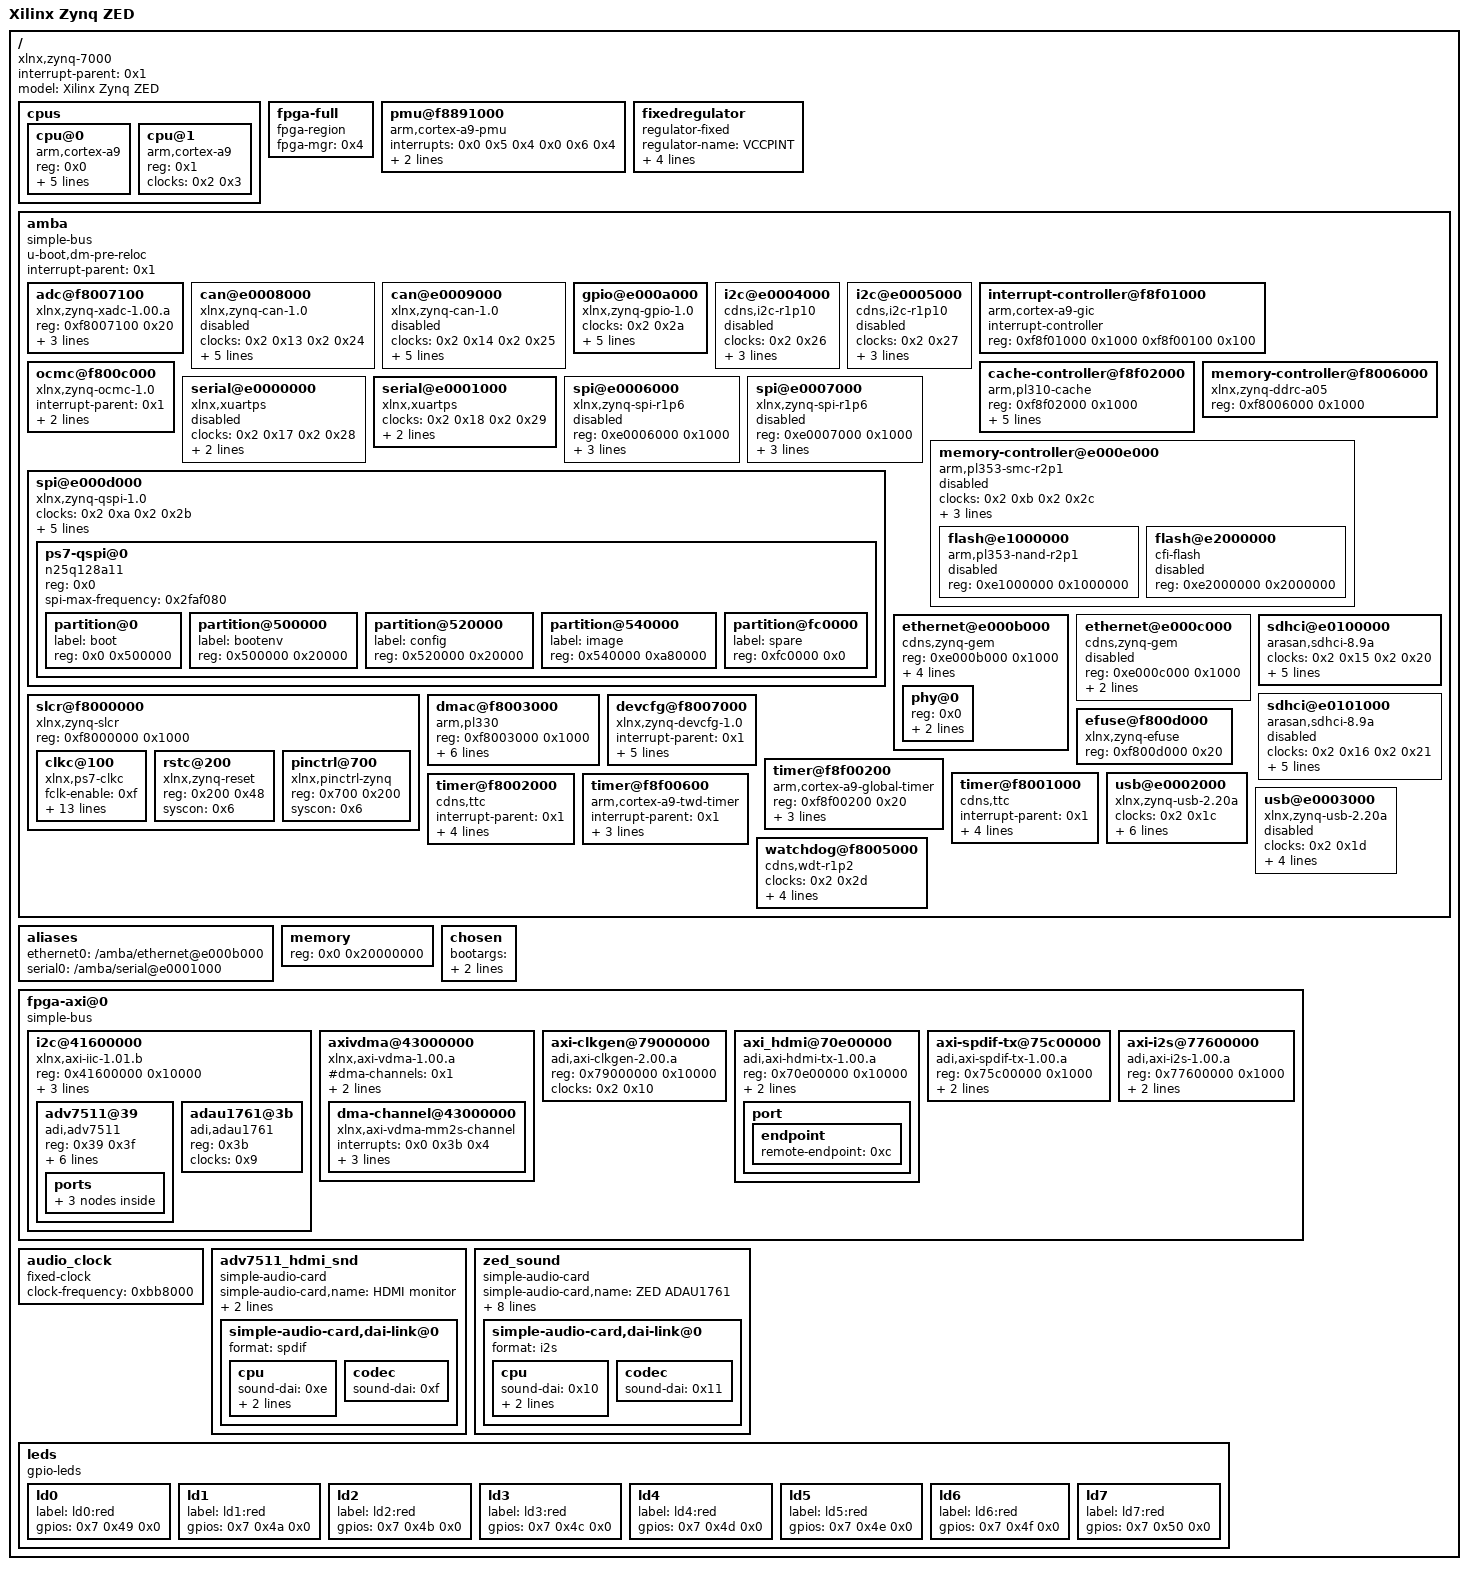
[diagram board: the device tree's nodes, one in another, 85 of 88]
/dts-v1/;

/ {
	#address-cells = <0x1>;
	#size-cells = <0x1>;
	compatible = "xlnx,zynq-7000";
	interrupt-parent = <0x1>;
	model = "Xilinx Zynq ZED";

	cpus {
		#address-cells = <0x1>;
		#size-cells = <0x0>;

		cpu@0 {
			compatible = "arm,cortex-a9";
			device_type = "cpu";
			reg = <0x0>;
			clocks = <0x2 0x3>;
			clock-latency = <0x3e8>;
			cpu0-supply = <0x3>;
			operating-points = <0xa2c2b 0xf4240 0x51616 0xf4240>;
		};

		cpu@1 {
			compatible = "arm,cortex-a9";
			device_type = "cpu";
			reg = <0x1>;
			clocks = <0x2 0x3>;
		};
	};

	fpga-full {
		compatible = "fpga-region";
		fpga-mgr = <0x4>;
		#address-cells = <0x1>;
		#size-cells = <0x1>;
		ranges;
	};

	pmu@f8891000 {
		compatible = "arm,cortex-a9-pmu";
		interrupts = <0x0 0x5 0x4 0x0 0x6 0x4>;
		interrupt-parent = <0x1>;
		reg = <0xf8891000 0x1000 0xf8893000 0x1000>;
	};

	fixedregulator {
		compatible = "regulator-fixed";
		regulator-name = "VCCPINT";
		regulator-min-microvolt = <0xf4240>;
		regulator-max-microvolt = <0xf4240>;
		regulator-boot-on;
		regulator-always-on;
		phandle = <0x3>;
	};

	amba {
		u-boot,dm-pre-reloc;
		compatible = "simple-bus";
		#address-cells = <0x1>;
		#size-cells = <0x1>;
		interrupt-parent = <0x1>;
		ranges;

		adc@f8007100 {
			compatible = "xlnx,zynq-xadc-1.00.a";
			reg = <0xf8007100 0x20>;
			interrupts = <0x0 0x7 0x4>;
			interrupt-parent = <0x1>;
			clocks = <0x2 0xc>;
		};

		can@e0008000 {
			compatible = "xlnx,zynq-can-1.0";
			status = "disabled";
			clocks = <0x2 0x13 0x2 0x24>;
			clock-names = "can_clk", "pclk";
			reg = <0xe0008000 0x1000>;
			interrupts = <0x0 0x1c 0x4>;
			interrupt-parent = <0x1>;
			tx-fifo-depth = <0x40>;
			rx-fifo-depth = <0x40>;
		};

		can@e0009000 {
			compatible = "xlnx,zynq-can-1.0";
			status = "disabled";
			clocks = <0x2 0x14 0x2 0x25>;
			clock-names = "can_clk", "pclk";
			reg = <0xe0009000 0x1000>;
			interrupts = <0x0 0x33 0x4>;
			interrupt-parent = <0x1>;
			tx-fifo-depth = <0x40>;
			rx-fifo-depth = <0x40>;
		};

		gpio@e000a000 {
			compatible = "xlnx,zynq-gpio-1.0";
			#gpio-cells = <0x2>;
			clocks = <0x2 0x2a>;
			gpio-controller;
			interrupt-controller;
			#interrupt-cells = <0x2>;
			interrupt-parent = <0x1>;
			interrupts = <0x0 0x14 0x4>;
			reg = <0xe000a000 0x1000>;
			phandle = <0x7>;
		};

		i2c@e0004000 {
			compatible = "cdns,i2c-r1p10";
			status = "disabled";
			clocks = <0x2 0x26>;
			interrupt-parent = <0x1>;
			interrupts = <0x0 0x19 0x4>;
			reg = <0xe0004000 0x1000>;
			#address-cells = <0x1>;
			#size-cells = <0x0>;
		};

		i2c@e0005000 {
			compatible = "cdns,i2c-r1p10";
			status = "disabled";
			clocks = <0x2 0x27>;
			interrupt-parent = <0x1>;
			interrupts = <0x0 0x30 0x4>;
			reg = <0xe0005000 0x1000>;
			#address-cells = <0x1>;
			#size-cells = <0x0>;
		};

		interrupt-controller@f8f01000 {
			compatible = "arm,cortex-a9-gic";
			#interrupt-cells = <0x3>;
			interrupt-controller;
			reg = <0xf8f01000 0x1000 0xf8f00100 0x100>;
			phandle = <0x1>;
		};

		cache-controller@f8f02000 {
			compatible = "arm,pl310-cache";
			reg = <0xf8f02000 0x1000>;
			interrupts = <0x0 0x2 0x4>;
			arm,data-latency = <0x3 0x2 0x2>;
			arm,tag-latency = <0x2 0x2 0x2>;
			cache-unified;
			cache-level = <0x2>;
		};

		memory-controller@f8006000 {
			compatible = "xlnx,zynq-ddrc-a05";
			reg = <0xf8006000 0x1000>;
		};

		ocmc@f800c000 {
			compatible = "xlnx,zynq-ocmc-1.0";
			interrupt-parent = <0x1>;
			interrupts = <0x0 0x3 0x4>;
			reg = <0xf800c000 0x1000>;
		};

		serial@e0000000 {
			compatible = "xlnx,xuartps", "cdns,uart-r1p8";
			status = "disabled";
			clocks = <0x2 0x17 0x2 0x28>;
			clock-names = "uart_clk", "pclk";
			reg = <0xe0000000 0x1000>;
			interrupts = <0x0 0x1b 0x4>;
		};

		serial@e0001000 {
			compatible = "xlnx,xuartps", "cdns,uart-r1p8";
			status = "okay";
			clocks = <0x2 0x18 0x2 0x29>;
			clock-names = "uart_clk", "pclk";
			reg = <0xe0001000 0x1000>;
			interrupts = <0x0 0x32 0x4>;
		};

		spi@e0006000 {
			compatible = "xlnx,zynq-spi-r1p6";
			reg = <0xe0006000 0x1000>;
			status = "disabled";
			interrupt-parent = <0x1>;
			interrupts = <0x0 0x1a 0x4>;
			clocks = <0x2 0x19 0x2 0x22>;
			clock-names = "ref_clk", "pclk";
			#address-cells = <0x1>;
			#size-cells = <0x0>;
		};

		spi@e0007000 {
			compatible = "xlnx,zynq-spi-r1p6";
			reg = <0xe0007000 0x1000>;
			status = "disabled";
			interrupt-parent = <0x1>;
			interrupts = <0x0 0x31 0x4>;
			clocks = <0x2 0x1a 0x2 0x23>;
			clock-names = "ref_clk", "pclk";
			#address-cells = <0x1>;
			#size-cells = <0x0>;
		};

		spi@e000d000 {
			clock-names = "ref_clk", "pclk";
			clocks = <0x2 0xa 0x2 0x2b>;
			compatible = "xlnx,zynq-qspi-1.0";
			status = "okay";
			interrupt-parent = <0x1>;
			interrupts = <0x0 0x13 0x4>;
			reg = <0xe000d000 0x1000>;
			#address-cells = <0x1>;
			#size-cells = <0x0>;
			is-dual = <0x0>;
			num-cs = <0x1>;

			ps7-qspi@0 {
				#address-cells = <0x1>;
				#size-cells = <0x1>;
				compatible = "n25q128a11";
				reg = <0x0>;
				spi-max-frequency = <0x2faf080>;

				partition@0 {
					label = "boot";
					reg = <0x0 0x500000>;
				};

				partition@500000 {
					label = "bootenv";
					reg = <0x500000 0x20000>;
				};

				partition@520000 {
					label = "config";
					reg = <0x520000 0x20000>;
				};

				partition@540000 {
					label = "image";
					reg = <0x540000 0xa80000>;
				};

				partition@fc0000 {
					label = "spare";
					reg = <0xfc0000 0x0>;
				};
			};
		};

		memory-controller@e000e000 {
			#address-cells = <0x1>;
			#size-cells = <0x1>;
			status = "disabled";
			clock-names = "memclk", "aclk";
			clocks = <0x2 0xb 0x2 0x2c>;
			compatible = "arm,pl353-smc-r2p1";
			interrupt-parent = <0x1>;
			interrupts = <0x0 0x12 0x4>;
			ranges;
			reg = <0xe000e000 0x1000>;

			flash@e1000000 {
				status = "disabled";
				compatible = "arm,pl353-nand-r2p1";
				reg = <0xe1000000 0x1000000>;
				#address-cells = <0x1>;
				#size-cells = <0x1>;
			};

			flash@e2000000 {
				status = "disabled";
				compatible = "cfi-flash";
				reg = <0xe2000000 0x2000000>;
				#address-cells = <0x1>;
				#size-cells = <0x1>;
			};
		};

		ethernet@e000b000 {
			compatible = "cdns,zynq-gem", "cdns,gem";
			reg = <0xe000b000 0x1000>;
			status = "okay";
			interrupts = <0x0 0x16 0x4>;
			clocks = <0x2 0x1e 0x2 0x1e 0x2 0xd>;
			clock-names = "pclk", "hclk", "tx_clk";
			#address-cells = <0x1>;
			#size-cells = <0x0>;
			phy-handle = <0x5>;
			phy-mode = "rgmii-id";

			phy@0 {
				device_type = "ethernet-phy";
				reg = <0x0>;
				marvell,reg-init = <0x3 0x10 0xff00 0x1e 0x3 0x11 0xfff0 0xa>;
				phandle = <0x5>;
			};
		};

		ethernet@e000c000 {
			compatible = "cdns,zynq-gem", "cdns,gem";
			reg = <0xe000c000 0x1000>;
			status = "disabled";
			interrupts = <0x0 0x2d 0x4>;
			clocks = <0x2 0x1f 0x2 0x1f 0x2 0xe>;
			clock-names = "pclk", "hclk", "tx_clk";
			#address-cells = <0x1>;
			#size-cells = <0x0>;
		};

		sdhci@e0100000 {
			compatible = "arasan,sdhci-8.9a";
			status = "okay";
			clock-names = "clk_xin", "clk_ahb";
			clocks = <0x2 0x15 0x2 0x20>;
			interrupt-parent = <0x1>;
			interrupts = <0x0 0x18 0x4>;
			reg = <0xe0100000 0x1000>;
			broken-adma2;
			disable-wp;
		};

		sdhci@e0101000 {
			compatible = "arasan,sdhci-8.9a";
			status = "disabled";
			clock-names = "clk_xin", "clk_ahb";
			clocks = <0x2 0x16 0x2 0x21>;
			interrupt-parent = <0x1>;
			interrupts = <0x0 0x2f 0x4>;
			reg = <0xe0101000 0x1000>;
			broken-adma2;
			disable-wp;
		};

		slcr@f8000000 {
			#address-cells = <0x1>;
			#size-cells = <0x1>;
			compatible = "xlnx,zynq-slcr", "syscon", "simple-mfd";
			reg = <0xf8000000 0x1000>;
			ranges;
			phandle = <0x6>;

			clkc@100 {
				#clock-cells = <0x1>;
				compatible = "xlnx,ps7-clkc";
				fclk-enable = <0xf>;
				clock-output-names = "armpll", "ddrpll", "iopll", "cpu_6or4x", "cpu_3or2x", "cpu_2x", "cpu_1x", "ddr2x", "ddr3x", "dci", "lqspi", "smc", "pcap", "gem0", "gem1", "fclk0", "fclk1", "fclk2", "fclk3", "can0", "can1", "sdio0", "sdio1", "uart0", "uart1", "spi0", "spi1", "dma", "usb0_aper", "usb1_aper", "gem0_aper", "gem1_aper", "sdio0_aper", "sdio1_aper", "spi0_aper", "spi1_aper", "can0_aper", "can1_aper", "i2c0_aper", "i2c1_aper", "uart0_aper", "uart1_aper", "gpio_aper", "lqspi_aper", "smc_aper", "swdt", "dbg_trc", "dbg_apb";
				reg = <0x100 0x100>;
				ps-clk-frequency = <0x1fca055>;
				phandle = <0x2>;
			};

			rstc@200 {
				compatible = "xlnx,zynq-reset";
				reg = <0x200 0x48>;
				#reset-cells = <0x1>;
				syscon = <0x6>;
			};

			pinctrl@700 {
				compatible = "xlnx,pinctrl-zynq";
				reg = <0x700 0x200>;
				syscon = <0x6>;
			};
		};

		dmac@f8003000 {
			compatible = "arm,pl330", "arm,primecell";
			reg = <0xf8003000 0x1000>;
			interrupt-parent = <0x1>;
			interrupt-names = "abort", "dma0", "dma1", "dma2", "dma3", "dma4", "dma5", "dma6", "dma7";
			interrupts = <0x0 0xd 0x4 0x0 0xe 0x4 0x0 0xf 0x4 0x0 0x10 0x4 0x0 0x11 0x4 0x0 0x28 0x4 0x0 0x29 0x4 0x0 0x2a 0x4 0x0 0x2b 0x4>;
			#dma-cells = <0x1>;
			#dma-channels = <0x8>;
			#dma-requests = <0x4>;
			clocks = <0x2 0x1b>;
			clock-names = "apb_pclk";
			phandle = <0xd>;
		};

		devcfg@f8007000 {
			compatible = "xlnx,zynq-devcfg-1.0";
			interrupt-parent = <0x1>;
			interrupts = <0x0 0x8 0x4>;
			reg = <0xf8007000 0x100>;
			clocks = <0x2 0xc 0x2 0xf 0x2 0x10 0x2 0x11 0x2 0x12>;
			clock-names = "ref_clk", "fclk0", "fclk1", "fclk2", "fclk3";
			syscon = <0x6>;
			phandle = <0x4>;
		};

		efuse@f800d000 {
			compatible = "xlnx,zynq-efuse";
			reg = <0xf800d000 0x20>;
		};

		timer@f8f00200 {
			compatible = "arm,cortex-a9-global-timer";
			reg = <0xf8f00200 0x20>;
			interrupts = <0x1 0xb 0x301>;
			interrupt-parent = <0x1>;
			clocks = <0x2 0x4>;
		};

		timer@f8001000 {
			interrupt-parent = <0x1>;
			interrupts = <0x0 0xa 0x4 0x0 0xb 0x4 0x0 0xc 0x4>;
			compatible = "cdns,ttc";
			clocks = <0x2 0x6>;
			reg = <0xf8001000 0x1000>;
		};

		timer@f8002000 {
			interrupt-parent = <0x1>;
			interrupts = <0x0 0x25 0x4 0x0 0x26 0x4 0x0 0x27 0x4>;
			compatible = "cdns,ttc";
			clocks = <0x2 0x6>;
			reg = <0xf8002000 0x1000>;
		};

		timer@f8f00600 {
			interrupt-parent = <0x1>;
			interrupts = <0x1 0xd 0x301>;
			compatible = "arm,cortex-a9-twd-timer";
			reg = <0xf8f00600 0x20>;
			clocks = <0x2 0x4>;
		};

		usb@e0002000 {
			compatible = "xlnx,zynq-usb-2.20a", "chipidea,usb2";
			status = "okay";
			clocks = <0x2 0x1c>;
			interrupt-parent = <0x1>;
			interrupts = <0x0 0x15 0x4>;
			reg = <0xe0002000 0x1000>;
			phy_type = "ulpi";
			dr_mode = "host";
			xlnx,phy-reset-gpio = <0x7 0x55 0x0>;
		};

		usb@e0003000 {
			compatible = "xlnx,zynq-usb-2.20a", "chipidea,usb2";
			status = "disabled";
			clocks = <0x2 0x1d>;
			interrupt-parent = <0x1>;
			interrupts = <0x0 0x2c 0x4>;
			reg = <0xe0003000 0x1000>;
			phy_type = "ulpi";
		};

		watchdog@f8005000 {
			clocks = <0x2 0x2d>;
			compatible = "cdns,wdt-r1p2";
			interrupt-parent = <0x1>;
			interrupts = <0x0 0x9 0x1>;
			reg = <0xf8005000 0x1000>;
			timeout-sec = <0xa>;
		};
	};

	aliases {
		ethernet0 = "/amba/ethernet@e000b000";
		serial0 = "/amba/serial@e0001000";
	};

	memory {
		device_type = "memory";
		reg = <0x0 0x20000000>;
	};

	chosen {
		bootargs = "console=ttyPS0,115200 root=/dev/mmcblk0p2 rw earlyprintk rootfstype=ext4 rootwait";
		linux,stdout-path = "/amba@0/uart@E0001000";
	};

	fpga-axi@0 {
		compatible = "simple-bus";
		#address-cells = <0x1>;
		#size-cells = <0x1>;
		ranges;

		i2c@41600000 {
			compatible = "xlnx,axi-iic-1.01.b", "xlnx,xps-iic-2.00.a";
			reg = <0x41600000 0x10000>;
			interrupt-parent = <0x1>;
			interrupts = <0x0 0x3a 0x4>;
			clocks = <0x2 0xf>;
			clock-names = "pclk";
			#size-cells = <0x0>;
			#address-cells = <0x1>;

			adv7511@39 {
				compatible = "adi,adv7511";
				reg = <0x39 0x3f>;
				reg-names = "primary", "edid";
				adi,input-depth = <0x8>;
				adi,input-colorspace = "yuv422";
				adi,input-clock = "1x";
				adi,input-style = <0x1>;
				adi,input-justification = "right";
				adi,clock-delay = <0x0>;
				#sound-dai-cells = <0x0>;
				phandle = <0xf>;

				ports {
					#address-cells = <0x1>;
					#size-cells = <0x0>;

					port@0 {
						reg = <0x0>;

						endpoint {
							remote-endpoint = <0x8>;
							phandle = <0xc>;
						};
					};

					port@1 {
						reg = <0x1>;
					};
				};
			};

			adau1761@3b {
				compatible = "adi,adau1761";
				reg = <0x3b>;
				clocks = <0x9>;
				clock-names = "mclk";
				#sound-dai-cells = <0x0>;
				phandle = <0x11>;
			};
		};

		axivdma@43000000 {
			compatible = "xlnx,axi-vdma-1.00.a";
			#address-cells = <0x1>;
			#size-cells = <0x1>;
			#dma-cells = <0x1>;
			#dma-channels = <0x1>;
			reg = <0x43000000 0x1000>;
			xlnx,num-fstores = <0x3>;
			phandle = <0xa>;

			dma-channel@43000000 {
				compatible = "xlnx,axi-vdma-mm2s-channel";
				interrupts = <0x0 0x3b 0x4>;
				xlnx,datawidth = <0x40>;
				xlnx,genlock-mode = <0x0>;
				xlnx,include-dre = <0x0>;
			};
		};

		axi-clkgen@79000000 {
			compatible = "adi,axi-clkgen-2.00.a";
			reg = <0x79000000 0x10000>;
			#clock-cells = <0x0>;
			clocks = <0x2 0x10>;
			phandle = <0xb>;
		};

		axi_hdmi@70e00000 {
			compatible = "adi,axi-hdmi-tx-1.00.a";
			reg = <0x70e00000 0x10000>;
			dmas = <0xa 0x0>;
			dma-names = "video";
			clocks = <0xb>;

			port {

				endpoint {
					remote-endpoint = <0xc>;
					phandle = <0x8>;
				};
			};
		};

		axi-spdif-tx@75c00000 {
			compatible = "adi,axi-spdif-tx-1.00.a";
			reg = <0x75c00000 0x1000>;
			dmas = <0xd 0x0>;
			dma-names = "tx";
			clocks = <0x2 0xf 0x9>;
			clock-names = "axi", "ref";
			#sound-dai-cells = <0x0>;
			phandle = <0xe>;
		};

		axi-i2s@77600000 {
			compatible = "adi,axi-i2s-1.00.a";
			reg = <0x77600000 0x1000>;
			dmas = <0xd 0x1 0xd 0x2>;
			dma-names = "tx", "rx";
			clocks = <0x2 0xf 0x9>;
			clock-names = "axi", "ref";
			#sound-dai-cells = <0x0>;
			phandle = <0x10>;
		};
	};

	audio_clock {
		compatible = "fixed-clock";
		#clock-cells = <0x0>;
		clock-frequency = <0xbb8000>;
		phandle = <0x9>;
	};

	adv7511_hdmi_snd {
		compatible = "simple-audio-card";
		simple-audio-card,name = "HDMI monitor";
		simple-audio-card,widgets = "Speaker", "Speaker";
		simple-audio-card,routing = "Speaker", "TX";

		simple-audio-card,dai-link@0 {
			format = "spdif";

			cpu {
				sound-dai = <0xe>;
				frame-master;
				bitclock-master;
			};

			codec {
				sound-dai = <0xf>;
			};
		};
	};

	zed_sound {
		compatible = "simple-audio-card";
		simple-audio-card,name = "ZED ADAU1761";
		simple-audio-card,widgets = "Microphone", "Mic In", "Headphone", "Headphone Out", "Line", "Line In", "Line", "Line Out";
		simple-audio-card,routing = "Line Out", "LOUT", "Line Out", "ROUT", "Headphone Out", "LHP", "Headphone Out", "RHP", "Mic In", "MICBIAS", "LINN", "Mic In", "RINN", "Mic In", "LAUX", "Line In", "RAUX", "Line In";

		simple-audio-card,dai-link@0 {
			format = "i2s";

			cpu {
				sound-dai = <0x10>;
				frame-master;
				bitclock-master;
			};

			codec {
				sound-dai = <0x11>;
			};
		};
	};

	leds {
		compatible = "gpio-leds";

		ld0 {
			label = "ld0:red";
			gpios = <0x7 0x49 0x0>;
		};

		ld1 {
			label = "ld1:red";
			gpios = <0x7 0x4a 0x0>;
		};

		ld2 {
			label = "ld2:red";
			gpios = <0x7 0x4b 0x0>;
		};

		ld3 {
			label = "ld3:red";
			gpios = <0x7 0x4c 0x0>;
		};

		ld4 {
			label = "ld4:red";
			gpios = <0x7 0x4d 0x0>;
		};

		ld5 {
			label = "ld5:red";
			gpios = <0x7 0x4e 0x0>;
		};

		ld6 {
			label = "ld6:red";
			gpios = <0x7 0x4f 0x0>;
		};

		ld7 {
			label = "ld7:red";
			gpios = <0x7 0x50 0x0>;
		};
	};
};
